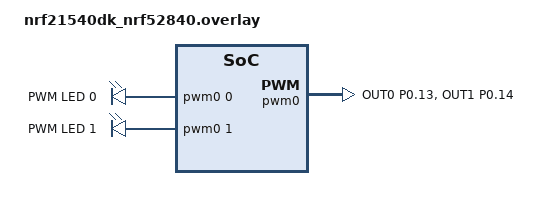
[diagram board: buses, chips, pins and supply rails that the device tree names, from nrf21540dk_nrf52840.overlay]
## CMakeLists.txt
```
cmake_minimum_required(VERSION 3.20.0)
find_package(Zephyr REQUIRED HINTS $ENV{ZEPHYR_BASE})

project(AutoGate)

target_sources(app PRIVATE src/main.c)
target_sources(app PRIVATE src/uartservice.c)
target_sources(app PRIVATE src/adc.c)
target_include_directories(app PRIVATE include)
```

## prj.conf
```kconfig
#
# Copyright (c) 2018 Nordic Semiconductor
#
# SPDX-License-Identifier: LicenseRef-Nordic-5-Clause
#
CONFIG_NCS_SAMPLES_DEFAULTS=y

CONFIG_BT=y
CONFIG_BT_PERIPHERAL=y
CONFIG_BT_NUS=y

CONFIG_BT_DEVICE_NAME="AutoGate"
#use fixed passkey instead of randomly generated
CONFIG_BT_FIXED_PASSKEY=y
CONFIG_BT_SMP=y  # Security Manager Protocol

CONFIG_SYSTEM_WORKQUEUE_STACK_SIZE=2040
#ADC CONFIG
CONFIG_ADC=y
CONFIG_PWM=y


# Enable bonding and encryption
CONFIG_BT_SMP_SC_ONLY=y 
CONFIG_BT_BONDABLE=y
```

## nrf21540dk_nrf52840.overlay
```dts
// To get started, press Ctrl+Space to bring up the completion menu and view the available nodes.

// You can also use the buttons in the sidebar to perform actions on nodes.
// Actions currently available include:

// * Enabling / disabling the node
// * Adding the bus to a bus
// * Removing the node
// * Connecting ADC channels

// For more help, browse the DeviceTree documentation at https://docs.zephyrproject.org/latest/guides/dts/index.html
// You can also visit the nRF DeviceTree extension documentation at https://docs.nordicsemi.com/bundle/nrf-connect-vscode/page/guides/ncs_configure_app.html#devicetree-support-in-the-extension
/* Enable and configure PWM0 and PWM1 */
/* Enable PWM0 and PWM1 */
/ {
	pwmleds {
		compatible = "pwm-leds";
		status = "okay";

		pwm_led0: pwm_led_0 {
			pwms = <&pwm0 0 PWM_MSEC(20) PWM_POLARITY_INVERTED>;
			label = "PWM LED 0";
		};

		pwm_led1: pwm_led_1 {
			pwms = <&pwm0 1 PWM_MSEC(20) PWM_POLARITY_INVERTED>;
			label = "PWM LED 1";
		};
	};
};

&pwm0 {
    status = "okay";
	pinctrl-0 = <&pwm0_default_alt>;
	pinctrl-1 = <&pwm0_sleep_alt>;
	pinctrl-names = "default", "sleep";
};

&pinctrl {
    pwm0_default_alt: pwm0_default_alt {
        group1 {
            psels = <NRF_PSEL(PWM_OUT0, 0, 13)>,
                    <NRF_PSEL(PWM_OUT1, 0, 14)>;
        };
    };

    pwm0_sleep_alt: pwm0_sleep_alt {
        group1 {
            psels = <NRF_PSEL(PWM_OUT0, 0, 13)>,
                    <NRF_PSEL(PWM_OUT1, 0, 14)>;
            low-power-enable;
        };
    };
};
```

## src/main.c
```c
/*
Auto gate:
button1 : to open/close both gate
button2 : to open/close both gate via tuya switch
button3 : connected to reid switch right
button4 : connected to reid swtich left
add comment
*/
#include "include/uartservice.h"
#include "include/adc.h"
#include <zephyr/kernel.h>
#include <zephyr/drivers/timer/nrf_rtc_timer.h>
#include <zephyr/drivers/gpio.h>
#include <zephyr/drivers/pwm.h>
int adc_value[2];                       //buffer for ADC
#define PWM_LED0_NODE DT_NODELABEL(pwm_led0)
#define PWM_LED1_NODE DT_NODELABEL(pwm_led1)
// Get the PWM device and channel information
static const struct pwm_dt_spec pwm_led0 = PWM_DT_SPEC_GET(PWM_LED0_NODE);
static const struct pwm_dt_spec pwm_led1 = PWM_DT_SPEC_GET(PWM_LED1_NODE);
// PWM DEFINITION
#define PERIOD                  1000     //ms
#define DUTYCYCLE               850      //10ms high

#define GATETIMERLIMIT          275     // 250 x 100ms timer = 25 seconds
#define SLEEPTIMER              375     // 300 x 100ms
/* The devicetree node identifier for the "led0" alias. */
#define LED0_NODE DT_ALIAS(led0)                        //for right actuator
#define LED1_NODE DT_ALIAS(led1)                        //left actuator
#define LED2_NODE DT_ALIAS(led2)                        //PWM Direction
#define LED3_NODE DT_ALIAS(led3)                        
#define SW1_NODE DT_ALIAS(sw0)                          //gate button 
#define SW2_NODE DT_ALIAS(sw1)                          //Tuya switch : look for momentary push signal
#define SW3_NODE DT_ALIAS(sw2)                          //reid switch right
#define SW4_NODE DT_ALIAS(sw3)                          //reid switch left

int btn0_count, btn1_count,btn2_count,btn3_count,sleepCount,ledFlashTimer;
/// for pwm /////////////////////////
uint8_t state = 0;
uint32_t pulse_width_ms0 = 0;  // Initial pulse width (off)
uint32_t pulse_width_ms1 = 20000;	//PWM_MSEC(20);
uint32_t step = 1;            //change this value to control the brightness step
uint32_t gateTimer = 0;
//flag..
bool gateIsClosing = false;
bool gateIsOpening = false;
bool gateIsClose = false;
bool pwm_LHisRunning = false;
bool pwm_RHisRunning = false;
bool timerisRunning = false;
// button0 
bool btn0_validPush = false;    //valid push is press (100-1900ms) and release
bool btn0_validHold = false;    //valid hold is press 2000ms
// button1 : tuya  switch
bool btn1_validPush = false; //valid contact is 100ms
// button2/3 : reid switch 
bool btn2_validContact = false;
bool btn3_validContact = false;

bool timeToReadADC = false;

//state machine
#define IDLESTATE 0
#define RUNNINGSTATE 1
#define MANUALSTATE 2
#define WAITSTATE 3
#define ERRORSTATE 4

/*
 * A build error on this line _means your board is unsupported.
 * See the sample documentation for information on how to fix this.
 */
static const struct gpio_dt_spec led_0 = GPIO_DT_SPEC_GET(LED0_NODE, gpios);  //gate actuator RH
static const struct gpio_dt_spec led_1 = GPIO_DT_SPEC_GET(LED1_NODE, gpios);  //gate actuator LH
static const struct gpio_dt_spec led_2 = GPIO_DT_SPEC_GET(LED2_NODE, gpios);
static const struct gpio_dt_spec led_3 = GPIO_DT_SPEC_GET(LED3_NODE, gpios);
static const struct gpio_dt_spec btn_0 = GPIO_DT_SPEC_GET(SW1_NODE, gpios);   //gate switch
static const struct gpio_dt_spec btn_1 = GPIO_DT_SPEC_GET(SW2_NODE, gpios);   //tuyaswitch
static const struct gpio_dt_spec btn_2 = GPIO_DT_SPEC_GET(SW3_NODE, gpios);   //Reid close sensor RH
static const struct gpio_dt_spec btn_3 = GPIO_DT_SPEC_GET(SW4_NODE, gpios);   //Reid close sensor LH

struct k_timer timer1,timer2;

// 10ms timer interrupt handler
void timer1_callback(struct k_timer *timer_id)
{
 //   printk("Timer1 expired!\n");
        /// debounce push button
        sleepCount++;
        // button0:
        // - press and release (100ms - 1500ms) : open/close/stop gate 
        // - long press (>1500ms) : resume open/close.
        // to open/close gate must push and release button
        // hold button for 2 seconds wil activate open/close until release
        if (gpio_pin_get_raw(btn_0.port,btn_0.pin)==0){
                sleepCount=0;
                if (btn0_count<200) btn0_count++;                
                if (btn0_count==200) {
                    btn0_validHold=true;
                //    printk("Button0 Is held /r/n ");
                }
        } else {
                if ((btn0_count>10) & (btn0_count<150)) btn0_validPush=true;
                  else
                  if (btn0_validHold==true) btn0_validHold=false;    
                btn0_count=0;
        //        printk("Button0 Is Released");
        }
        // debunce for tuya gate...
        // button1:
        // - switch is closed : min 100ms contact, once register button must be release to register another conctact
        if (gpio_pin_get_raw(btn_1.port,btn_1.pin)==0){
                sleepCount=0;
                if (btn1_count<1000) btn1_count++;
        } else {
                if (btn1_count>10) btn1_validPush=true;
                btn1_count=0;
        }
       // debunce for tuya gate...
       // - switch is closed : min 100ms contact, once register button must be release to register another conctact
        if (gpio_pin_get_raw(btn_2.port,btn_2.pin)==0){
                sleepCount=0;
                if (btn2_count<5) {
                        btn2_count++;   
                        if (btn2_count==5) {
                                btn2_validContact=true;    
                                printk("Reid RH switch valid contact /r/n");
                        }
                }
        } else {
                if (btn2_validContact) {
                        btn2_validContact = false;
                        printk("Reid RH switch release /r/n");
                }
                btn2_count=0;
        }
        // - switch is closed : min 100ms contact, once register button must be release to register another conctact
        if (gpio_pin_get_raw(btn_3.port,btn_3.pin)==0){
                sleepCount=0;
                if (btn3_count<5) {
                        btn3_count++;   
                        if (btn3_count==5) {
                                btn3_validContact=true;    
                                printk("Reid LH switch valid contact /r/n");
                        }
                }
        } else {
                if (btn3_validContact){
                        btn3_validContact=false;
                        printk("Reid LH switch release /r/n");
                }
                btn3_count=0;   
        }        

}
  
 
// called when gate is moving
void timer2_callback(struct k_timer *timer_id){
        ledFlashTimer++; 
        if (ledFlashTimer>4) {
                gpio_pin_toggle_dt(&led_3);
                ledFlashTimer=0;
        }
        
        timeToReadADC=true;
        gateTimer--;
//	gpio_pin_toggle_dt(&led_3);
//	pulse_width_ms1+=1000;
//	if(pulse_width_ms1>20000) pulse_width_ms1=20000;
//	pwm_set_pulse_dt(&pwm_led1, PWM_USEC(pulse_width_ms1));
}

K_TIMER_DEFINE(timer1, timer1_callback, NULL);
K_TIMER_DEFINE(timer2, timer2_callback, NULL);

// Interrupt Handler Function
// Interrupt Handler Function
// any button_pressed will start timer1 
void button_pressed(const struct device *dev, struct gpio_callback *cb, uint32_t pins) {
            printk("Button Pressed!");
                btn0_count=0;
        	gpio_pin_interrupt_configure_dt(&btn_0,GPIO_INT_DISABLE);
                gpio_pin_interrupt_configure_dt(&btn_1,GPIO_INT_DISABLE);
                gpio_pin_interrupt_configure_dt(&btn_2,GPIO_INT_DISABLE);
                gpio_pin_interrupt_configure_dt(&btn_3,GPIO_INT_DISABLE);
                //if(!timerisRunning){
                //   timerisRunning=true;
                   k_timer_start(&timer1, K_MSEC(10), K_MSEC(10)); // 10-msecond timer
                   sleepCount=0;     //sleep timer = 30 seconds
                //}
        
        }

void checkGateStatus(){
        /*see current gate status
        1. if RH and LH are close : set direction as 1 
        2. if RH and LH are open  : set direction as 0
        3. if RH and LH are not in the same position : set directeion as 0
        */
       if (btn2_validContact&btn3_validContact) gateIsClose=true; else gateIsClose=false;

}
void openGate(){
        printk("Opening Gate %d \n\a",state);
        gateIsOpening=true;
        gateIsClosing=false;
        pwm_set_dt(&pwm_led0,PERIOD,DUTYCYCLE);
        pwm_LHisRunning=true;
        pwm_set_dt(&pwm_led1,PERIOD,DUTYCYCLE);
        pwm_RHisRunning=true;        
        gpio_pin_set_dt(&led_3,0);      //pwm direction
        timeToReadADC=false;
        gateTimer=GATETIMERLIMIT;
        ledFlashTimer=0;
        k_timer_start(&timer2, K_MSEC(100), K_MSEC(100)); // 100 msecond timer

}
void closeGate(){
        
        gateIsOpening=false;
        if(!btn2_validContact){
                pwm_set_dt(&pwm_led0,PERIOD,DUTYCYCLE);
                pwm_LHisRunning=true;
        }
        if(!btn3_validContact){
                pwm_set_dt(&pwm_led1,PERIOD,DUTYCYCLE);
                pwm_RHisRunning=true;
        }
        if (pwm_LHisRunning | pwm_RHisRunning) {
                printk("Closing Gate %d \n\a",state);
                gpio_pin_set_dt(&led_3,1);
                timeToReadADC=false;
                gateTimer=GATETIMERLIMIT;
                ledFlashTimer=0;
                k_timer_start(&timer2, K_MSEC(100), K_MSEC(100)); // 100 msecond timer
                gateIsClosing=true;
        }
}
void stopGate(){
        printk("Gate Stopped %d\n\a",state);
        pwm_set_dt(&pwm_led0,PERIOD,0);
        pwm_set_dt(&pwm_led1,PERIOD,0);
        gpio_pin_set_dt(&led_0,1);
        gpio_pin_set_dt(&led_1,1);
        pwm_LHisRunning=false;
        pwm_RHisRunning=false;
        k_timer_stop(&timer2);                  //stop timer2 (for reading adc)        
}


int stateMachine(){
        switch(state) {
                case IDLESTATE:
                        // check reid sensor to see
                        // wait for button pressed
                        checkGateStatus();
                        if (btn0_validPush||btn1_validPush) {
                                // toggle gate
                                btn0_validPush=false;
                                btn1_validPush=false;
                                state=RUNNINGSTATE;
                                // decide whether to open or close gate
                                if(gateIsClose) {
                                        // gate is close, open the gate
                                        openGate();
                                        break;
                                } else {
                                        // get could be open or partially open
                                        // just reverse previous direction
                                        if (gateIsClosing) openGate();
                                        else {
                                               closeGate();
                                               if (!gateIsClosing) state=IDLESTATE;   //gate already closed
                                        }
                                        break;

                                }

                        } else
                        if (btn0_validHold) {
                                state=MANUALSTATE;
                                if (gateIsClosing) closeGate(); //continue previous movement
                                else if (gateIsOpening) openGate();  //continue previous movement
                                else {  //no movement since powerup
                                        if(gateIsClose) {
                                                openGate();
                                        } else {;
                                                closeGate();
                                        }

                                }

                         }
                        break;
                case RUNNINGSTATE:
                        // gate is opening / closing 
                        // if button is pressed, stop gate
                        // otherwise check current draw, if current draw exceeds threshold stop the gate
                        // wait for button pressed:
                        if (btn0_validHold) {
                                stopGate();
                                state=WAITSTATE;
                                break;
                        } else
                        if (btn0_validPush||btn1_validPush) {
                                btn0_validPush=false;
                                btn1_validPush=false;
                                stopGate();
                                state=0;
                                break;
                        }
                        // read current draw and check for overcurrent
                        if (timeToReadADC) {
                                readADC(&adc_value);
                                timeToReadADC=false;
                                if(!pwm_LHisRunning) adc_value[0]=0;
                                if(!pwm_RHisRunning) adc_value[1]=0;
                                printk("ADC Value: %d and %d\n", adc_value[0],adc_value[1]);
                                bt_nus_send(NULL, adc_value, 2);
                        }
                        // when closing, check if reid switch is detected close
                        if (gateIsClosing){
                                if (btn2_validContact) {
                                        pwm_set_dt(&pwm_led0,PERIOD,0);
                                        gpio_pin_set_dt(&led_0,0);
                                        pwm_LHisRunning=false;
                                        if (!pwm_RHisRunning) {
                                                state=0;
                                                k_timer_stop(&timer2);                  //stop timer2 (for reading adc) 
                                                break;
                                        }
                                }
                                if (btn3_validContact) {
                                        pwm_set_dt(&pwm_led1,PERIOD,0);
                                        gpio_pin_set_dt(&led_1,0);
                                        pwm_RHisRunning=false;
                                        if (!pwm_LHisRunning) {
                                                state=0;
                                                k_timer_stop(&timer2);                  //stop timer2 (for reading adc) 
                                                break;
                                        }
                                }
                        }
                        // check if time limit to open/close gate reached
                        if (gateTimer==0) {
                                stopGate();
                                if(btn0_validHold) state=WAITSTATE;
                                else state=0;
                        }

                        break;
                case MANUALSTATE:
                        // gate is manually opening / closing 
                        // if button is pressed, stop gate
                        // otherwise check current draw, if current draw exceeds threshold stop the gate
                        // wait for butto pressed:
                        if (!btn0_validHold) {
                                stopGate();
                                state=0;
                                break;
                        }
                        if (timeToReadADC) {
                                readADC(&adc_value);
                                timeToReadADC=false;
                                if(!pwm_LHisRunning) adc_value[0]=0;
                                if(!pwm_RHisRunning) adc_value[1]=0;
                                printk("ADC Value: %d and %d\n", adc_value[0],adc_value[1]);
                                bt_nus_send(NULL, adc_value, 2);

                        }
                        // when closing, check if reid switch is detected close
                        if (gateIsClosing){
                                if (btn2_validContact) {
                                        pwm_set_dt(&pwm_led0,PERIOD,0);
                                        gpio_pin_set_dt(&led_0,0);
                                        pwm_LHisRunning=false;
                                        if (!pwm_RHisRunning) {
                                                state=WAITSTATE;
                                                k_timer_stop(&timer2);                  //stop timer2 (for reading adc) 
                                                break;
                                        }
                                }
                                if (btn3_validContact) {
                                        pwm_set_dt(&pwm_led1,PERIOD,0);
                                        gpio_pin_set_dt(&led_1,0);
                                        pwm_RHisRunning=false;
                                        if (!pwm_LHisRunning) {
                                                state=WAITSTATE;
                                                k_timer_stop(&timer2);                  //stop timer2 (for reading adc) 
                                                break;
                                        }
                                }
                        }
                                                // check if time limit to open/close gate reached
                        if (gateTimer==0) {
                                stopGate();
                                state=WAITSTATE;
                        }
                        break;
                case WAITSTATE:
                        if (!btn0_validHold) state=0;
                        break;
                        // gate has stopped must wait


        }
}
        
int main(void)
{       int err;
        err = initUsartService();
        if (err) return 0;
        err= initADC();
        if (err) return 0;
    
        // pwm ///////////////////////////////
        if (!device_is_ready(pwm_led0.dev)) {
		printk("Error: PWM device %s is not ready\n", pwm_led0.dev->name);
		return 1;
	}
	if (!device_is_ready(pwm_led1.dev)) {
		printk("Error: PWM device %s is not ready\n", pwm_led1.dev->name);
		return 1;
	}

	if (!gpio_is_ready_dt(&led_0)|!gpio_is_ready_dt(&led_1) | !gpio_is_ready_dt(&led_2)|!gpio_is_ready_dt(&led_3)) return 0;
		
	if (!gpio_is_ready_dt(&btn_0)|!gpio_is_ready_dt(&btn_1)) return 0;
	
        err = gpio_pin_configure_dt(&led_0, GPIO_OUTPUT_ACTIVE);
	if (err) return 0;
	err = gpio_pin_configure_dt(&led_1, GPIO_OUTPUT_ACTIVE);
	if (err) return 0;
	err = gpio_pin_configure_dt(&led_2, GPIO_OUTPUT_ACTIVE);
	if (err) return 0;
	err = gpio_pin_configure_dt(&led_3, GPIO_OUTPUT_ACTIVE);
	if (err) return 0;
	err = gpio_pin_configure_dt(&btn_0,GPIO_INPUT |GPIO_PULL_UP);
	if (err) return 0;
	err = gpio_pin_configure_dt(&btn_1,GPIO_INPUT |GPIO_PULL_UP);
	if (err) return 0;
        err = gpio_pin_configure_dt(&btn_2,GPIO_INPUT |GPIO_PULL_UP);
	if (err) return 0;
        err = gpio_pin_configure_dt(&btn_3,GPIO_INPUT |GPIO_PULL_UP);
	if (err) return 0;
        // setup interrupt for button0
	err = gpio_pin_interrupt_configure_dt(&btn_0,GPIO_INT_EDGE_FALLING);
	if (err) return 0;
	err = gpio_pin_interrupt_configure_dt(&btn_1,GPIO_INT_EDGE_FALLING);
	if (err) return 0;
        err = gpio_pin_interrupt_configure_dt(&btn_2,GPIO_INT_EDGE_FALLING);
	if (err) return 0;
	err = gpio_pin_interrupt_configure_dt(&btn_3,GPIO_INT_EDGE_FALLING);
	if (err) return 0;
        gpio_pin_set_dt(&led_0,0);
        gpio_pin_set_dt(&led_1,0);
        gpio_pin_set_dt(&led_2,0);
        gpio_pin_set_dt(&led_3,0);
        // Initialize and add callback
/*
        static struct gpio_callback btn_0_cb,btn_1_cb;
	gpio_init_callback(&btn_0_cb, button0_pressed, BIT(btn_0.pin));
	gpio_add_callback(btn_0.port, &btn_0_cb);
	gpio_init_callback(&btn_1_cb, button1_pressed, BIT(btn_1.pin));
	gpio_add_callback(btn_1.port, &btn_1_cb);
*/
        static struct gpio_callback btn_cb;
        //interupt on any button press
        gpio_init_callback(&btn_cb,button_pressed,BIT(btn_0.pin)|BIT(btn_1.pin)|BIT(btn_2.pin)|BIT(btn_3.pin));
        gpio_add_callback(btn_0.port,&btn_cb);
        printk("All innitialised and ready...");
        for (;;) {
                //	dk_set_led(RUN_STATUS_LED, (++blink_status) % 2);
                if (sleepCount>3000) {
                        printk("Deep Sleep \r\n");
                        k_timer_stop(&timer1);                  //stop timer2 (for reading adc)      
                        k_timer_stop(&timer2);
                        stopGate();
                 //       gpio_pin_interrupt_configure_dt(&btn_0,GPIO_INT_ENABLE);
                       // setup interrupt for button0
	                err = gpio_pin_interrupt_configure_dt(&btn_0,GPIO_INT_EDGE_FALLING);
	                if (err) return 0;
	                err = gpio_pin_interrupt_configure_dt(&btn_1,GPIO_INT_EDGE_FALLING);
	                if (err) return 0;
                        err = gpio_pin_interrupt_configure_dt(&btn_2,GPIO_INT_EDGE_FALLING);
	                if (err) return 0;
	                err = gpio_pin_interrupt_configure_dt(&btn_3,GPIO_INT_EDGE_FALLING);
                        k_cpu_idle();  // Sleep until an interrupt occurs       k_sleep(K_MSEC(1000));
                        sleepCount=0;
                        if (state!=MANUALSTATE) state=0;
                        printk("wake up \r\n");

                }
                stateMachine();
               
                }
}

          
```

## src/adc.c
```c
#include <zephyr/drivers/adc.h>

#define ADC_DEVICE_NAME DT_LABEL(DT_NODELABEL(adc))  // Get ADC device
#define ADC_CHANNEL1 0   // Select the ADC channel AIN0
#define ADC_CHANNEL2 1   // Select the ADC channel AIN1

#define ADC_RESOLUTION 8  // Set 12-bit resolution
#define ADC_GAIN ADC_GAIN_4  // Set gain (adjust as needed)
#define ADC_REFERENCE ADC_REF_INTERNAL  // Internal reference voltage
#define ADC_ACQUISITION_TIME ADC_ACQ_TIME(ADC_ACQ_TIME_MICROSECONDS, 10) // 10us

static const struct device *adc_dev = DEVICE_DT_GET(DT_NODELABEL(adc));
static int16_t adc_buffer[2];  // Buffer to store ADC value

static struct adc_channel_cfg adc_cfg1 = {
    .gain = ADC_GAIN,
    .reference = ADC_REFERENCE,
    .acquisition_time = ADC_ACQUISITION_TIME,
    .channel_id = ADC_CHANNEL1,
    .differential = 0,
    .input_positive = SAADC_CH_PSELP_PSELP_AnalogInput0, // Maps to P0.0
};
static struct adc_channel_cfg adc_cfg2 = {
    .gain = ADC_GAIN,
    .reference = ADC_REFERENCE,
    .acquisition_time = ADC_ACQUISITION_TIME,
    .channel_id = ADC_CHANNEL2,
    .differential= 0,
    .input_positive = SAADC_CH_PSELP_PSELP_AnalogInput1, // Maps to P0.02
};
static struct adc_sequence adc_seq = {
    .channels = BIT(ADC_CHANNEL1)|BIT(ADC_CHANNEL2),
    .buffer = &adc_buffer,
    .buffer_size = sizeof(adc_buffer),
    .resolution = ADC_RESOLUTION,
};



int initADC(void) {
    int err;

    if (!device_is_ready(adc_dev)) {
        printk("ADC device not ready\n");
        return 1;
    }

    err = adc_channel_setup(adc_dev, &adc_cfg1);
    if (err) {
        printk("ADC channel setup failed (err %d)\n", err);
        return 0;
    }
    err = adc_channel_setup(adc_dev, &adc_cfg2);
    if (err) {
        printk("ADC channel setup failed (err %d)\n", err);
        return 1;
    }
    
    
    printk("ADC initialized, reading values...\n");
    return 0;
}

int readADC(int *buffer){
        int err;
   
        err = adc_read(adc_dev, &adc_seq);
        if (err) {
            printk("ADC read failed (err %d)\n", err);
            return err;
        } else {
            buffer[0]=adc_buffer[0];
            buffer[1]=adc_buffer[1];
 //           printk("ADC Value: %d and %d\n", adc_buffer[0],adc_buffer[1]);
            return 0;
        }
}

    
```

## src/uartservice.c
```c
/*
 * Copyright (c) 2018 Nordic Semiconductor ASA
 *
 * SPDX-License-Identifier: LicenseRef-Nordic-5-Clause
 */

//#include <zephyr/types.h>
//#include <stddef.h>
//#include <string.h>
//#include <errno.h>
#include <zephyr/sys/printk.h>
//#include <zephyr/sys/byteorder.h>
#include <zephyr/kernel.h>
//#include <zephyr/drivers/gpio.h>
//#include <soc.h>

#include <zephyr/bluetooth/bluetooth.h>
#include <zephyr/bluetooth/hci.h>
//#include <zephyr/bluetooth/conn.h>
//#include <zephyr/bluetooth/uuid.h>
//#include <zephyr/bluetooth/gatt.h>

//#include <bluetooth/services/lbs.h>
#include <bluetooth/services/nus.h>
#include <zephyr/settings/settings.h>
//#include "include\uartservice.h"
//#include <dk_buttons_and_leds.h>

#define DEVICE_NAME             CONFIG_BT_DEVICE_NAME
#define DEVICE_NAME_LEN         (sizeof(DEVICE_NAME) - 1)


#define RUN_STATUS_LED          DK_LED1
#define CON_STATUS_LED          DK_LED2
#define RUN_LED_BLINK_INTERVAL  1000

#define USER_LED                DK_LED3

#define USER_BUTTON             DK_BTN1_MSK

char rxBuf[10],txBuf[10];

static const struct bt_data ad[] = {
    BT_DATA_BYTES(BT_DATA_FLAGS, (BT_LE_AD_GENERAL | BT_LE_AD_NO_BREDR)),
    BT_DATA(BT_DATA_NAME_COMPLETE, DEVICE_NAME, DEVICE_NAME_LEN),
    BT_DATA_BYTES(BT_DATA_UUID128_ALL, BT_UUID_NUS_VAL),  // Advertise NUS UUID
};

static void connected(struct bt_conn *conn, uint8_t err)
{
	if (err) {
		printk("Connection failed, err 0x%02x %s\n", err, bt_hci_err_to_str(err));
		return;
	}
    printk("Connected. Enforcing secure pairing...\n");
    bt_conn_set_security(conn, BT_SECURITY_L2);  // Force Passkey Entry
}

static void disconnected(struct bt_conn *conn, uint8_t reason)
{
	printk("Disconnected, reason 0x%02x %s\n", reason, bt_hci_err_to_str(reason));
//	bt_unpair(BT_ID_DEFAULT, NULL);
//	dk_set_led_off(CON_STATUS_LED);
}

#ifdef CONFIG_BT_SMP
static void security_changed(struct bt_conn *conn, bt_security_t level,
			     enum bt_security_err err)
{
	char addr[BT_ADDR_LE_STR_LEN];

	bt_addr_le_to_str(bt_conn_get_dst(conn), addr, sizeof(addr));

	if (!err) {
		printk("Security changed: %s level %u\n", addr, level);
	} else {
		printk("Security failed: %s level %u err %d %s\n", addr, level, err,
		       bt_security_err_to_str(err));
	}
	bt_unpair(BT_ID_DEFAULT, NULL);
}
#endif



#if defined(CONFIG_BT_SMP)
static void auth_passkey_display(struct bt_conn *conn, unsigned int passkey)
{
	char addr[BT_ADDR_LE_STR_LEN];

	bt_addr_le_to_str(bt_conn_get_dst(conn), addr, sizeof(addr));

	printk("Passkey for %s: %06u\n", addr, passkey);
}

static void auth_cancel(struct bt_conn *conn)
{
	char addr[BT_ADDR_LE_STR_LEN];

	bt_addr_le_to_str(bt_conn_get_dst(conn), addr, sizeof(addr));

	printk("Pairing cancelled: %s\n", addr);
}

static void pairing_complete(struct bt_conn *conn, bool bonded)
{
	char addr[BT_ADDR_LE_STR_LEN];

	bt_addr_le_to_str(bt_conn_get_dst(conn), addr, sizeof(addr));

	printk("Pairing completed: %s, bonded: %d\n", addr, bonded);
}

static void pairing_failed(struct bt_conn *conn, enum bt_security_err reason)
{
	char addr[BT_ADDR_LE_STR_LEN];

	bt_addr_le_to_str(bt_conn_get_dst(conn), addr, sizeof(addr));

	printk("Pairing failed conn: %s, reason %d %s\n", addr, reason,
	       bt_security_err_to_str(reason));
}

static struct bt_conn_auth_cb conn_auth_callbacks = {
	.passkey_display = auth_passkey_display,
	.passkey_entry = NULL,
	.cancel = auth_cancel,
};

static struct bt_conn_auth_info_cb conn_auth_info_callbacks = {
	.pairing_complete = pairing_complete,
	.pairing_failed = pairing_failed
};
#else
static struct bt_conn_auth_cb conn_auth_callbacks;
static struct bt_conn_auth_info_cb conn_auth_info_callbacks;
#endif

//static void app_led_cb(bool led_state)
//{
//	dk_set_led(USER_LED, led_state);
//}

//static bool app_button_cb(void)
//{
//	return app_button_state;
//}
static void nus_data_received(struct bt_conn *conn, const uint8_t *data, uint16_t length)
{
    // Print the received data
    printk("Received length: %d\n", length);
	for (int count=0;count < length;count++){
		printk("%c",data[count]);
	}
	printk("\n");
	bt_nus_send(NULL, data, length);
//	for (int count=0;count<length;count++){
//		bt_nus_send(NULL,txBuf,length);
//	}
}

static void nus_data_sent(struct bt_conn *conn)
{
    // Print whether sending data was successful
	int err;
    if (err == 0) {
        printk("Data successfully sent\n");
    } else {
        printk("Data sending failed, err: %d\n", err);
    }
}
static const struct bt_nus_cb nus_callbacks = {
    .received = nus_data_received,  // Data received callback
    .sent = nus_data_sent,      // Data sent callback
};
//static struct bt_lbs_cb lbs_callbacs = {
//	.led_cb    = app_led_cb,
//	.button_cb = app_button_cb,
//};

/*
static void button_changed(uint32_t button_state, uint32_t has_changed)
{
	if (has_changed & USER_BUTTON) {
		uint32_t user_button_state = button_state & USER_BUTTON;

		bt_lbs_send_button_state(user_button_state);
		app_button_state = user_button_state ? true : false;
	}
}
*/
/*
static int init_button(void)
{
	int err;

	err = dk_buttons_init(button_changed);
	if (err) {
		printk("Cannot init buttons (err: %d)\n", err);
	}

	return err;
}
*/
int initUsartService(void)
{
	int err;
	
	printk("Starting Bluetooth Peripheral LBS example\n");

	if (IS_ENABLED(CONFIG_BT_SMP)) {
		err = bt_conn_auth_cb_register(&conn_auth_callbacks);
		if (err) {
			printk("Failed to register authorization callbacks.\n");
			return 1;
		}

		err = bt_conn_auth_info_cb_register(&conn_auth_info_callbacks);
		if (err) {
			printk("Failed to register authorization info callbacks.\n");
			return 1;
		}
	}

	// Set a fixed passkey (6-digit number)
    err = bt_passkey_set(654321);
    if (err) {
        printk("Failed to set passkey (err %d)\n", err);
    } else {
        printk("Fixed passkey set to 123456\n");
    }
	
	BT_CONN_CB_DEFINE(conn_callbacks) = {
		.connected        = connected,
		.disconnected     = disconnected,
	#ifdef CONFIG_BT_SMP
		.security_changed = security_changed,
	#endif
	};

	err = bt_enable(NULL);
	if (err) {
		printk("Bluetooth init failed (err %d)\n", err);
		return 1;
	}

	printk("Bluetooth initialized\n");
	//comment out for testing : to force pairing mode all the time
	if (IS_ENABLED(CONFIG_SETTINGS)) {
		settings_load();
	}

	/*
	err = bt_lbs_init(&lbs_callbacs);
	if (err) {
		printk("Failed to init LBS (err:%d)\n", err);
		return 0;
	}*/
	err = bt_nus_init(&nus_callbacks);
    if (err) {
        printk("Failed to initialize NUS (err: %d)\n", err);
        return 1;
    }

//	err = bt_le_adv_start(BT_LE_ADV_CONN, ad, ARRAY_SIZE(ad),sd, ARRAY_SIZE(sd));
	err = bt_le_adv_start(BT_LE_ADV_CONN, ad, ARRAY_SIZE(ad), NULL, 0);
	if (err) {
		printk("Advertising failed to start (err %d)\n", err);
		return 1;
	}

	printk("Advertising successfully started\n");
    return 0;

//	for (;;) {
//	//	dk_set_led(RUN_STATUS_LED, (++blink_status) % 2);
//		k_sleep(K_MSEC(RUN_LED_BLINK_INTERVAL));
//	}
}
```
